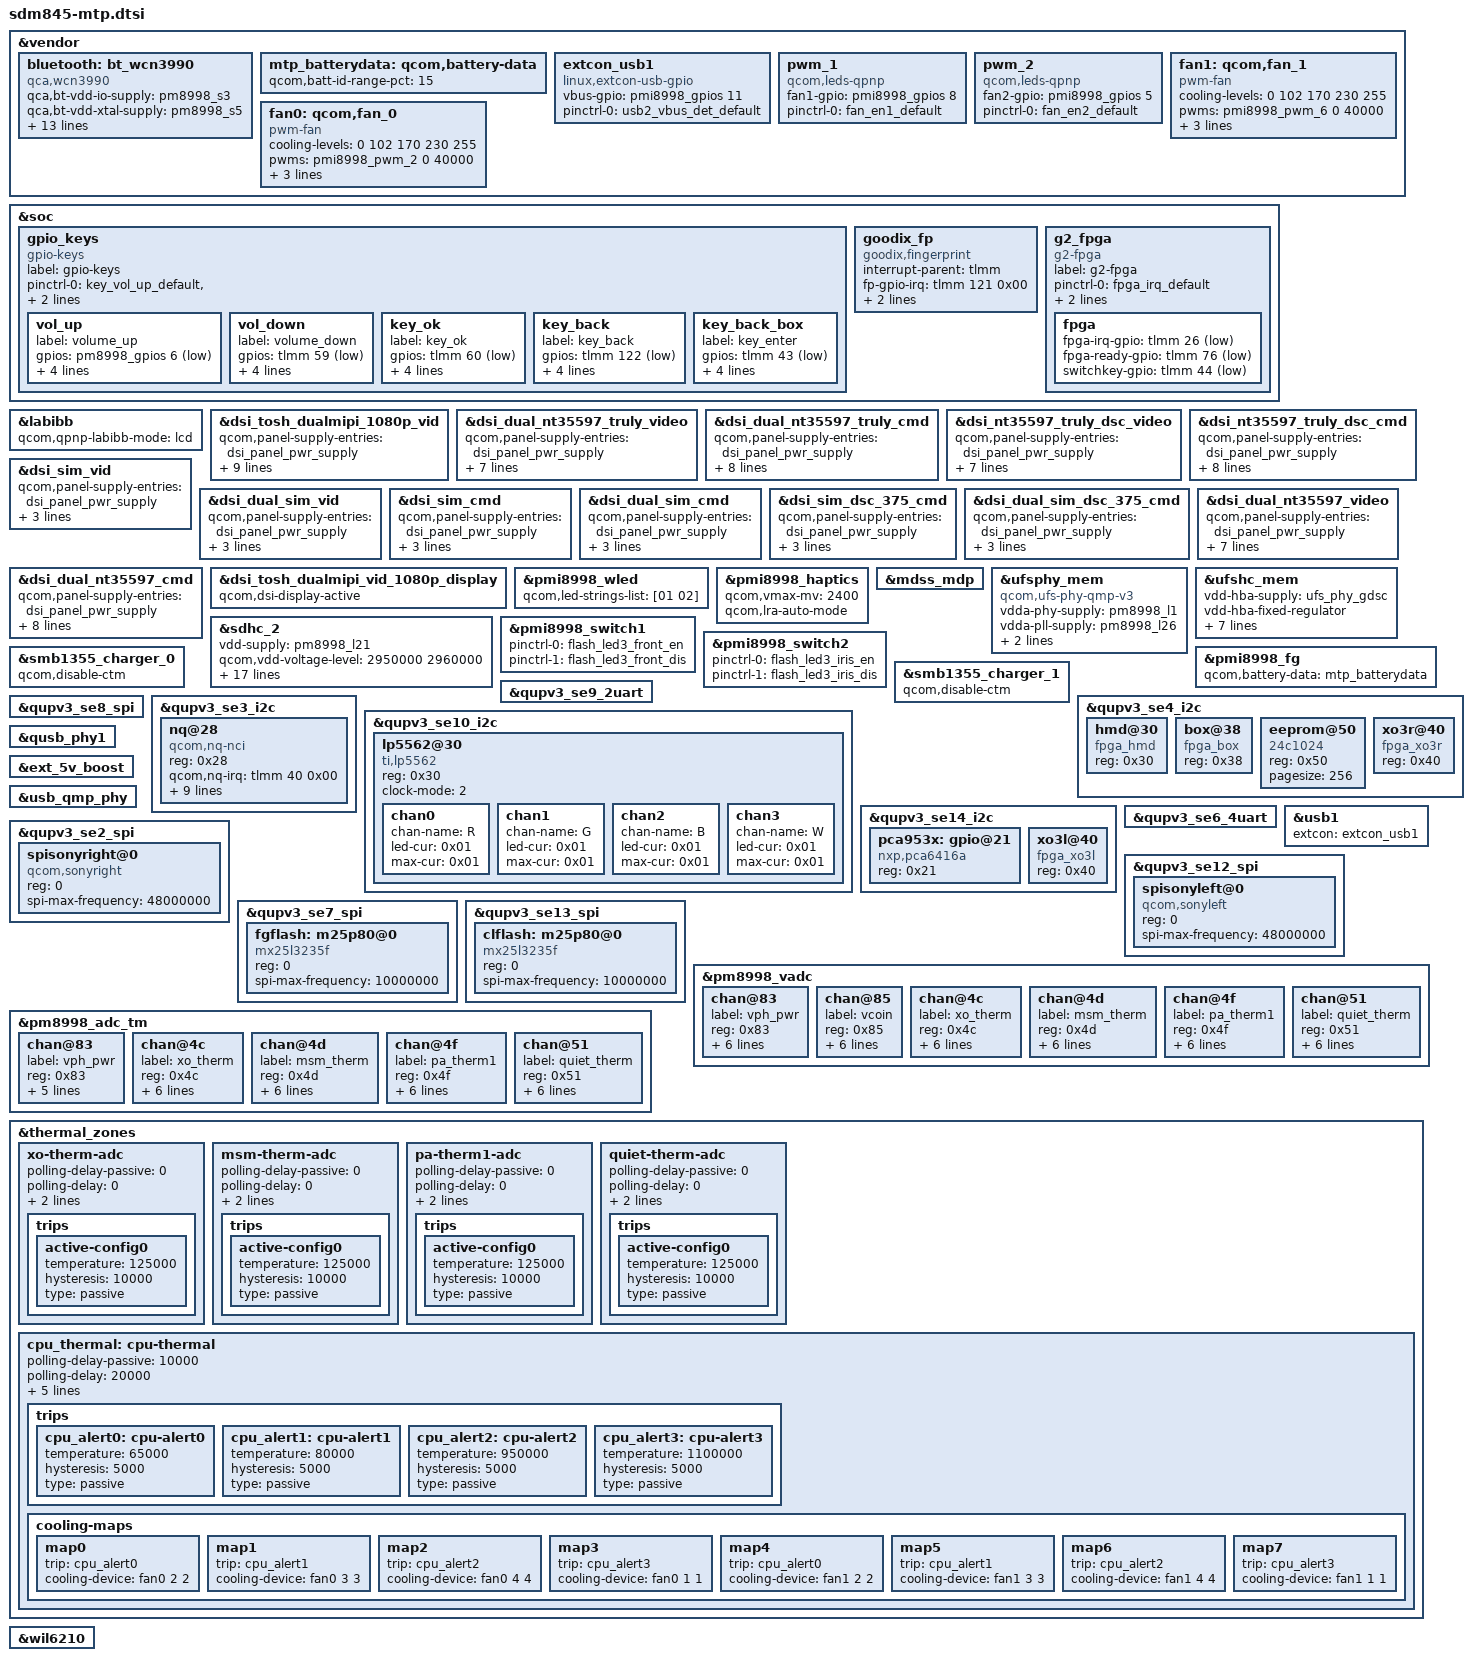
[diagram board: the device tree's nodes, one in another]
/* Copyright (c) 2016-2018, The Linux Foundation. All rights reserved.
 *
 * This program is free software; you can redistribute it and/or modify
 * it under the terms of the GNU General Public License version 2 and
 * only version 2 as published by the Free Software Foundation.
 *
 * This program is distributed in the hope that it will be useful,
 * but WITHOUT ANY WARRANTY; without even the implied warranty of
 * MERCHANTABILITY or FITNESS FOR A PARTICULAR PURPOSE.  See the
 * GNU General Public License for more details.
 */

#include <dt-bindings/gpio/gpio.h>
#include "sdm845-pmic-overlay.dtsi"
#include "sdm845-pinctrl-overlay.dtsi"
#include "sdm845-camera-sensor-mtp.dtsi"
#include "smb1355.dtsi"

&vendor {
	bluetooth: bt_wcn3990 {
		compatible = "qca,wcn3990";
		qca,bt-vdd-io-supply = <&pm8998_s3>;
		qca,bt-vdd-xtal-supply = <&pm8998_s5>;
		qca,bt-vdd-core-supply = <&pm8998_l7>;
		qca,bt-vdd-pa-supply = <&pm8998_l17>;
		qca,bt-vdd-ldo-supply = <&pm8998_l25>;

		qca,bt-vdd-io-voltage-level = <1352000 1352000>;
		qca,bt-vdd-xtal-voltage-level = <2040000 2040000>;
		qca,bt-vdd-core-voltage-level = <1800000 1800000>;
		qca,bt-vdd-pa-voltage-level = <1304000 1304000>;
		qca,bt-vdd-ldo-voltage-level = <3312000 3312000>;

		qca,bt-vdd-io-current-level = <1>; /* LPM/PFM */
		qca,bt-vdd-xtal-current-level = <1>; /* LPM/PFM */
		qca,bt-vdd-core-current-level = <1>; /* LPM/PFM */
		qca,bt-vdd-pa-current-level = <1>; /* LPM/PFM */
		qca,bt-vdd-ldo-current-level = <1>; /* LPM/PFM */
	};
};

&soc {
		gpio_keys {
                compatible = "gpio-keys";
                label = "gpio-keys";
                pinctrl-names = "default";
                
		/*pinctrl-0 = <&key_vol_up_default
			     &key_cam_snapshot_default
			     &key_cam_focus_default>;*/
                pinctrl-0 = <&key_vol_up_default
                             &key_vol_down_default
                            // &key_menu_default
                             &key_ok_default
                             //&key_up_default
                             //&key_down_default
                             //&key_left_default
                             &key_back_default
                             //&key_right_default
                             &key_back_box_default
			     //&key_switch_default
			     //&key_switch_backup_default
			    >;
	        vol_up {
                        label = "volume_up";
                        gpios = <&pm8998_gpios 6 GPIO_ACTIVE_LOW>;
                        linux,input-type = <1>;
                        linux,code = <115>;
                        //gpio-key,wakeup;
                        debounce-interval = <15>;
                        linux,can-disable;
                };
                vol_down {
                        label = "volume_down";
                        gpios = <&tlmm 59 GPIO_ACTIVE_LOW>;
                        linux,input-type = <1>;
                        linux,code = <114>;
                        //gpio-key,wakeup;
                        debounce-interval = <15>;
                        linux,can-disable;
                };
	
                 key_ok{
                        label = "key_ok";
                        gpios = <&tlmm 60 GPIO_ACTIVE_LOW>;
                        linux,input-type = <1>;
                        linux,code = <353>;
                        //gpio-key,wakeup;
                        debounce-interval = <15>;
                        linux,can-disable;
                }; 
		/*key_switch{
                        label = "key_switch";
                        gpios = <&tlmm 44 GPIO_ACTIVE_LOW>;
                        linux,input-type = <1>;
                        linux,code = <600>;
                        //gpio-key,wakeup;
                        debounce-interval = <15>;
                        linux,can-disable;
                }; 

                key_switch_backup{
                        label = "key_switch_backup";
                        gpios = <&tlmm 125 GPIO_ACTIVE_LOW>;
                        linux,input-type = <1>;
                        linux,code = <601>;
                        //gpio-key,wakeup;
                        debounce-interval = <15>;
                        linux,can-disable;
                }; 

                key_up{
                        label = "key_up";
                        gpios = <&tlmm 44 GPIO_ACTIVE_LOW>;//61
                        linux,input-type = <1>;
                        linux,code = <103>;
                        //gpio-key,wakeup;
                        debounce-interval = <15>;
                        linux,can-disable;
                };

                 key_down{
                        label = "key_down";
                        gpios = <&tlmm 125 GPIO_ACTIVE_LOW>;//62
                        linux,input-type = <1>;
                        linux,code = <108>;
                        //gpio-key,wakeup;
                        debounce-interval = <15>;
                        linux,can-disable;
                };
                key_left{
                        label = "key_left";
                        gpios = <&tlmm 62 GPIO_ACTIVE_LOW>;//63
                        linux,input-type = <1>;
                        linux,code = <105>;
                        //gpio-key,wakeup;
                        debounce-interval = <15>;
                        linux,can-disable;

                };*/
                key_back{
                        label = "key_back";
                        gpios = <&tlmm 122 GPIO_ACTIVE_LOW>;
                        linux,input-type = <1>;
                        linux,code = <158>;
                        //gpio-key,wakeup;
                        debounce-interval = <15>;
                        linux,can-disable;
                };

               /* key_right{
                        label = "key_right";
                        gpios = <&tlmm 87 GPIO_ACTIVE_LOW>;
                        linux,input-type = <1>;
                        linux,code = <106>;
                        //gpio-key,wakeup;
                        debounce-interval = <15>;
                        linux,can-disable;
                };*/
               key_back_box{
                        label = "key_enter";
                        gpios = <&tlmm 43 GPIO_ACTIVE_LOW>;
                        linux,input-type = <1>;
                        linux,code = <158>;
                        //gpio-key,wakeup;
                        debounce-interval = <15>;
                        linux,can-disable;
                };

           /*    key_menu{
                        label = "key_menu";
                        gpios = <&tlmm 44 GPIO_ACTIVE_LOW>;
                        linux,input-type = <1>;
                        linux,code = <102>;
                        //gpio-key,wakeup;
                        debounce-interval = <15>;
                        linux,can-disable;
                };
*/
               
           

	};
        
    //goodix GF3206 fp
        goodix_fp{
		compatible = "goodix,fingerprint";

		interrupt-parent = <&tlmm>;

		fp-gpio-irq = <&tlmm 121 0x00>;

		fp-gpio-reset = <&tlmm 91 0x00>;
                
                vdd-fp-supply = <&pm8998_l19>;

		status = "ok";
        };

        g2_fpga{
            compatible = "g2-fpga";
            label = "g2-fpga";
            pinctrl-names = "default";
            pinctrl-0 = <&fpga_irq_default>;
            pinctrl-1 = <&fpga_ready_default>;
	    pinctrl-2 = <&switchkey_default>;
            fpga{
                fpga-irq-gpio = <&tlmm 26 GPIO_ACTIVE_LOW>;
                fpga-ready-gpio = <&tlmm 76 GPIO_ACTIVE_LOW>;
		switchkey-gpio = <&tlmm 44 GPIO_ACTIVE_LOW>;
            };
        };
};


&labibb {
	status = "ok";
	qcom,qpnp-labibb-mode = "lcd";
};

//chad add nedplus begin
//&dsi_tosh_dualmipi_vid {
&dsi_tosh_dualmipi_1080p_vid {
	qcom,panel-supply-entries = <&dsi_panel_pwr_supply>;
	qcom,mdss-dsi-bl-pmic-control-type = "bl_ctrl_wled";//it should be not used
	qcom,mdss-dsi-bl-min-level = <1>;
	qcom,mdss-dsi-bl-max-level = <4095>;
	qcom,mdss-dsi-mode-sel-gpio-state = "dual_port";
        qcom,platform-pwr-en = <&tlmm 114 0>;//control 10v for sony panel
	qcom,platform-tc-gpio = <&tlmm 24 0>;//pull up 1.2v for toshiba
	qcom,platform-reset-gpio = <&tlmm 6 0>;
        qcom,platform-stby-gpio = <&tlmm 10 0>;

};
//chad add nedplus end


&dsi_dual_nt35597_truly_video {
	qcom,panel-supply-entries = <&dsi_panel_pwr_supply>;
	qcom,mdss-dsi-bl-pmic-control-type = "bl_ctrl_wled";
	qcom,mdss-dsi-bl-min-level = <1>;
	qcom,mdss-dsi-bl-max-level = <4095>;
	qcom,mdss-dsi-mode-sel-gpio-state = "dual_port";
	qcom,panel-mode-gpio = <&tlmm 52 0>;
	qcom,platform-reset-gpio = <&tlmm 6 0>;
};

&dsi_dual_nt35597_truly_cmd {
	qcom,panel-supply-entries = <&dsi_panel_pwr_supply>;
	qcom,mdss-dsi-bl-pmic-control-type = "bl_ctrl_wled";
	qcom,mdss-dsi-bl-min-level = <1>;
	qcom,mdss-dsi-bl-max-level = <4095>;
	qcom,mdss-dsi-mode-sel-gpio-state = "dual_port";
	qcom,panel-mode-gpio = <&tlmm 52 0>;
	qcom,platform-reset-gpio = <&tlmm 6 0>;
	qcom,platform-te-gpio = <&tlmm 10 0>;
};

&dsi_nt35597_truly_dsc_video {
	qcom,panel-supply-entries = <&dsi_panel_pwr_supply>;
	qcom,mdss-dsi-bl-pmic-control-type = "bl_ctrl_wled";
	qcom,mdss-dsi-bl-min-level = <1>;
	qcom,mdss-dsi-bl-max-level = <4095>;
	qcom,mdss-dsi-mode-sel-gpio-state = "single_port";
	qcom,panel-mode-gpio = <&tlmm 52 0>;
	qcom,platform-reset-gpio = <&tlmm 6 0>;
};

&dsi_nt35597_truly_dsc_cmd {
	qcom,panel-supply-entries = <&dsi_panel_pwr_supply>;
	qcom,mdss-dsi-bl-pmic-control-type = "bl_ctrl_wled";
	qcom,mdss-dsi-bl-min-level = <1>;
	qcom,mdss-dsi-bl-max-level = <4095>;
	qcom,mdss-dsi-mode-sel-gpio-state = "single_port";
	qcom,panel-mode-gpio = <&tlmm 52 0>;
	qcom,platform-reset-gpio = <&tlmm 6 0>;
	qcom,platform-te-gpio = <&tlmm 10 0>;
};

&dsi_sim_vid {
	qcom,panel-supply-entries = <&dsi_panel_pwr_supply>;
	qcom,mdss-dsi-bl-pmic-control-type = "bl_ctrl_wled";
	qcom,platform-reset-gpio = <&tlmm 6 0>;
};

&dsi_dual_sim_vid {
	qcom,panel-supply-entries = <&dsi_panel_pwr_supply>;
	qcom,mdss-dsi-bl-pmic-control-type = "bl_ctrl_wled";
	qcom,platform-reset-gpio = <&tlmm 6 0>;
};

&dsi_sim_cmd {
	qcom,panel-supply-entries = <&dsi_panel_pwr_supply>;
	qcom,mdss-dsi-bl-pmic-control-type = "bl_ctrl_wled";
	qcom,platform-reset-gpio = <&tlmm 6 0>;
};

&dsi_dual_sim_cmd {
	qcom,panel-supply-entries = <&dsi_panel_pwr_supply>;
	qcom,mdss-dsi-bl-pmic-control-type = "bl_ctrl_wled";
	qcom,platform-reset-gpio = <&tlmm 6 0>;
};

&dsi_sim_dsc_375_cmd {
	qcom,panel-supply-entries = <&dsi_panel_pwr_supply>;
	qcom,mdss-dsi-bl-pmic-control-type = "bl_ctrl_wled";
	qcom,platform-reset-gpio = <&tlmm 6 0>;
};

&dsi_dual_sim_dsc_375_cmd {
	qcom,panel-supply-entries = <&dsi_panel_pwr_supply>;
	qcom,mdss-dsi-bl-pmic-control-type = "bl_ctrl_wled";
	qcom,platform-reset-gpio = <&tlmm 6 0>;
};

&dsi_dual_nt35597_video {
	qcom,panel-supply-entries = <&dsi_panel_pwr_supply>;
	qcom,mdss-dsi-bl-pmic-control-type = "bl_ctrl_wled";
	qcom,mdss-dsi-bl-min-level = <1>;
	qcom,mdss-dsi-bl-max-level = <4095>;
	qcom,mdss-dsi-mode-sel-gpio-state = "dual_port";
	qcom,panel-mode-gpio = <&tlmm 52 0>;
	qcom,platform-reset-gpio = <&tlmm 6 0>;
};

&dsi_dual_nt35597_cmd {
	qcom,panel-supply-entries = <&dsi_panel_pwr_supply>;
	qcom,mdss-dsi-bl-pmic-control-type = "bl_ctrl_wled";
	qcom,mdss-dsi-bl-min-level = <1>;
	qcom,mdss-dsi-bl-max-level = <4095>;
	qcom,mdss-dsi-mode-sel-gpio-state = "dual_port";
	qcom,panel-mode-gpio = <&tlmm 52 0>;
	qcom,platform-reset-gpio = <&tlmm 6 0>;
	qcom,platform-te-gpio = <&tlmm 10 0>;
};


//chad add for nedplus begin
//&dsi_tosh_dualmipi_vid_display {
&dsi_tosh_dualmipi_vid_1080p_display {
	qcom,dsi-display-active;
};

//chad add for nedplus end 

&pmi8998_wled {
	status = "okay";
	qcom,led-strings-list = [01 02];
};

&pmi8998_haptics {
	qcom,vmax-mv = <2400>;
	qcom,lra-auto-mode;
	status = "okay";
};

&mdss_mdp {
	#cooling-cells = <2>;
};

&ufsphy_mem {
	compatible = "qcom,ufs-phy-qmp-v3";

	vdda-phy-supply = <&pm8998_l1>; /* 0.88v */
	vdda-pll-supply = <&pm8998_l26>; /* 1.2v */
	vdda-phy-max-microamp = <62900>;
	vdda-pll-max-microamp = <18300>;

	status = "ok";
};

&ufshc_mem {
	vdd-hba-supply = <&ufs_phy_gdsc>;
	vdd-hba-fixed-regulator;
	vcc-supply = <&pm8998_l20>;
	vcc-voltage-level = <2950000 2960000>;
	vccq2-supply = <&pm8998_s4>;
	vcc-max-microamp = <600000>;
	vccq2-max-microamp = <600000>;

	qcom,vddp-ref-clk-supply = <&pm8998_l2>;
	qcom,vddp-ref-clk-max-microamp = <100>;

	status = "ok";
};

&sdhc_2 {
	vdd-supply = <&pm8998_l21>;
	qcom,vdd-voltage-level = <2950000 2960000>;
	qcom,vdd-current-level = <200 800000>;

	vdd-io-supply = <&pm8998_l13>;
	qcom,vdd-io-voltage-level = <1808000 2960000>;
	qcom,vdd-io-current-level = <200 22000>;

	pinctrl-names = "active", "sleep", "ds_400KHz",
			"ds_50MHz", "ds_100MHz", "ds_200MHz";
	pinctrl-0 = <&sdc2_clk_on  &sdc2_cmd_on &sdc2_data_on &storage_cd>;
	pinctrl-1 = <&sdc2_clk_off &sdc2_cmd_off &sdc2_data_off &storage_cd>;
	pinctrl-2 = <&sdc2_clk_ds_400KHz
			&sdc2_cmd_ds_400KHz &sdc2_data_ds_400KHz>;
	pinctrl-3 = <&sdc2_clk_ds_50MHz
			&sdc2_cmd_ds_50MHz &sdc2_data_ds_50MHz>;
	pinctrl-4 = <&sdc2_clk_ds_100MHz
			&sdc2_cmd_ds_100MHz &sdc2_data_ds_100MHz>;
	pinctrl-5 = <&sdc2_clk_ds_200MHz
			&sdc2_cmd_ds_200MHz &sdc2_data_ds_200MHz>;

	cd-gpios = <&tlmm 126 GPIO_ACTIVE_HIGH>;

	status = "ok";
};

&pmi8998_switch1 {
	pinctrl-names = "led_enable", "led_disable";
	pinctrl-0 = <&flash_led3_front_en>;
	pinctrl-1 = <&flash_led3_front_dis>;
};

&pmi8998_switch2 {
	pinctrl-names = "led_enable", "led_disable";
	pinctrl-0 = <&flash_led3_iris_en>;
	pinctrl-1 = <&flash_led3_iris_dis>;
};

&vendor {
	mtp_batterydata: qcom,battery-data {
		qcom,batt-id-range-pct = <15>;
		#include "Lenovo_4044A4_6400mAh_PMI8998GUI20058.dtsi"
	};

	extcon_usb1: extcon_usb1 {
		compatible = "linux,extcon-usb-gpio";
		vbus-gpio = <&pmi8998_gpios 11 GPIO_ACTIVE_HIGH>;

		pinctrl-names = "default";
		pinctrl-0 = <&usb2_vbus_det_default>;
	};

	pwm_1: pwm_1 {
		compatible = "qcom,leds-qpnp";
		fan1-gpio = <&pmi8998_gpios 8 0>;

		pinctrl-names = "default";
		pinctrl-0 = <&fan_en1_default>;
	};

	pwm_2: pwm_2 {
		compatible = "qcom,leds-qpnp";
		fan2-gpio = <&pmi8998_gpios 5 0>;

		pinctrl-names = "default";
		pinctrl-0 = <&fan_en2_default>;
	};

	fan1: qcom,fan_1 {
		compatible = "pwm-fan";
		#cooling-cells = <2>;
		cooling-levels = <0 102 170 230 255>;
		pwms = <&pmi8998_pwm_6 0 40000>;
		pwm-names = "fan1";
		#pwm-cells = <2>;
		fan-en-gpio = <&tlmm 92 0>;
		fan0-en-gpio = <&tlmm 123 0>;
	};

	fan0: qcom,fan_0 {
		compatible = "pwm-fan";
		#cooling-cells = <2>;
		cooling-levels = <0 102 170 230 255>;
		pwms = <&pmi8998_pwm_2 0 40000>;
		pwm-names = "fan0";
		#pwm-cells = <2>;
		fan-en-gpio = <&tlmm 92 0>;
		fan1-en-gpio = <&tlmm 124 0>;
	};
};

&pmi8998_fg {
	qcom,battery-data = <&mtp_batterydata>;
};

&smb1355_charger_0 {
	status = "ok";
	qcom,disable-ctm;
};

&smb1355_charger_1 {
	status = "ok";
	qcom,disable-ctm;
};

&qupv3_se9_2uart {
	status = "ok";
};

&qupv3_se8_spi {
	status = "ok";
};

&qupv3_se3_i2c {
	status = "ok";
    	nq@28{
		compatible = "qcom,nq-nci";
		reg = <0x28>;
		qcom,nq-irq = <&tlmm 40 0x00>;
		qcom,nq-ven = <&tlmm 12 0x00>;
		qcom,nq-firm = <&tlmm 39 0x00>;
		qcom,nq-clkreq = <&pm8998_gpios 21 0x00>;
		qcom,nq-esepwr = <&tlmm 116 0x00>;
		interrupt-parent = <&tlmm>;
		//qcom,clk-src = "BBCLK3";  //CS3
		interrupts = <40 0>;
		interrupt-names = "nfc_irq";
		pinctrl-names = "nfc_active", "nfc_suspend";
		pinctrl-0 = <&nfc_int_active
			     &nfc_enable_active
			     &nfc_clk_default>;
		pinctrl-1 = <&nfc_int_suspend &nfc_enable_suspend>;
		//clocks = <&clock_rpmh RPMH_LN_BB_CLK3>;  //CS3
		//clock-names = "ref_clk";  //CS3
	};
};

&qupv3_se4_i2c { //for FPGA version
	status = "ok";
	hmd@30 {
		compatible = "fpga_hmd";
		reg = <0x30>;
	};

	box@38 {
		compatible = "fpga_box";
		reg = <0x38>;
	};

	eeprom@50 {
		compatible = "24c1024";
		reg = <0x50>;
		pagesize = <256>;
	};

	xo3r@40 {
		compatible = "fpga_xo3r";
		reg = <0x40>;
	};
 };

&qupv3_se10_i2c {
        status = "ok";
        lp5562@30 {
                        compatible = "ti,lp5562";
                        reg = <0x30>;
                        clock-mode = /bits/8 <2>;

                        chan0 {
                                chan-name = "R";
                                led-cur = /bits/ 8 <0x01>;
                                max-cur = /bits/ 8 <0x01>;
                        };

                        chan1 {
                                chan-name = "G";
                                led-cur = /bits/ 8 <0x01>;
                                max-cur = /bits/ 8 <0x01>;
                        };

                        chan2 {
                                chan-name = "B";
                                led-cur = /bits/ 8 <0x01>;
                                max-cur = /bits/ 8 <0x01>;
                        };

                        chan3 {
                                chan-name = "W";
                                led-cur = /bits/ 8 <0x01>;
                                max-cur = /bits/ 8 <0x01>;
                           };
             };

};

&qupv3_se14_i2c {
	status = "ok";
	pca953x: gpio@21 {
		compatible = "nxp,pca6416a";
                reg = <0x21>;
	};

	xo3l@40 {
		compatible = "fpga_xo3l";
		reg = <0x40>;
	};
};

&qupv3_se6_4uart {
	status = "ok";
};

&usb1 {
	status = "okay";
	extcon = <&extcon_usb1>;
};

&qusb_phy1 {
	status = "okay";
};

&ext_5v_boost {
	status = "ok";
};

&usb_qmp_phy {
	status = "okay";
};


//chad add for nedplus begin
 &qupv3_se2_spi { 
		status = "ok";
		spisonyright@0{
		compatible ="qcom,sonyright";
		reg = <0>;
		spi-max-frequency = <48000000>;
		}; 
		};

&qupv3_se12_spi { 
		status = "ok";
		spisonyleft@0{
		compatible ="qcom,sonyleft";
		reg = <0>;
		spi-max-frequency = <48000000>;
		}; 
		};

//chad add for nedplus end
//ZD add for spi Flash begin

&qupv3_se7_spi { 
		status = "ok";
		fgflash: m25p80@0 {
		#address-cells = <1>;
		#size-cells = <1>;
		compatible = "mx25l3235f";
		reg = <0>;
		spi-max-frequency = <10000000>;
		//m25p,fast-read;
	};
};

&qupv3_se13_spi { 
		status = "ok";
		clflash: m25p80@0 {
		#address-cells = <1>;
		#size-cells = <1>;
		compatible = "mx25l3235f";
		reg = <0>;
		spi-max-frequency = <10000000>;
		//m25p,fast-read;
	};
};
//ZD add for spi Flash end
&pm8998_vadc {
	chan@83 {
		label = "vph_pwr";
		reg = <0x83>;
		qcom,decimation = <2>;
		qcom,pre-div-channel-scaling = <1>;
		qcom,calibration-type = "absolute";
		qcom,scale-function = <0>;
		qcom,hw-settle-time = <0>;
		qcom,fast-avg-setup = <0>;
	}; 

	chan@85 {
		label = "vcoin";
		reg = <0x85>;
		qcom,decimation = <2>;
		qcom,pre-div-channel-scaling = <1>;
		qcom,calibration-type = "absolute";
		qcom,scale-function = <0>;
		qcom,hw-settle-time = <0>;
		qcom,fast-avg-setup = <0>;
	};

	chan@4c {
		label = "xo_therm";
		reg = <0x4c>;
		qcom,decimation = <2>;
		qcom,pre-div-channel-scaling = <0>;
		qcom,calibration-type = "ratiometric";
		qcom,scale-function = <4>;
		qcom,hw-settle-time = <2>;
		qcom,fast-avg-setup = <0>;
	};

	chan@4d {
		label = "msm_therm";
		reg = <0x4d>;
		qcom,decimation = <2>;
		qcom,pre-div-channel-scaling = <0>;
		qcom,calibration-type = "ratiometric";
		qcom,scale-function = <2>;
		qcom,hw-settle-time = <2>;
		qcom,fast-avg-setup = <0>;
	};

	chan@4f {
		label = "pa_therm1";
		reg = <0x4f>;
		qcom,decimation = <2>;
		qcom,pre-div-channel-scaling = <0>;
		qcom,calibration-type = "ratiometric";
		qcom,scale-function = <2>;
		qcom,hw-settle-time = <2>;
		qcom,fast-avg-setup = <0>;
	};

	chan@51 {
		label = "quiet_therm";
		reg = <0x51>;
		qcom,decimation = <2>;
		qcom,pre-div-channel-scaling = <0>;
		qcom,calibration-type = "ratiometric";
		qcom,scale-function = <2>;
		qcom,hw-settle-time = <2>;
		qcom,fast-avg-setup = <0>;
	};
};

&pm8998_adc_tm {
	chan@83 {
		label = "vph_pwr";
		reg = <0x83>;
		qcom,pre-div-channel-scaling = <1>;
		qcom,calibration-type = "absolute";
		qcom,scale-function = <0>;
		qcom,hw-settle-time = <0>;
		qcom,btm-channel-number = <0x60>;
	};

	chan@4c {
		label = "xo_therm";
		reg = <0x4c>;
		qcom,pre-div-channel-scaling = <0>;
		qcom,calibration-type = "ratiometric";
		qcom,scale-function = <4>;
		qcom,hw-settle-time = <2>;
		qcom,btm-channel-number = <0x68>;
		qcom,thermal-node;
	};

	chan@4d {
		label = "msm_therm";
		reg = <0x4d>;
		qcom,pre-div-channel-scaling = <0>;
		qcom,calibration-type = "ratiometric";
		qcom,scale-function = <2>;
		qcom,hw-settle-time = <2>;
		qcom,btm-channel-number = <0x70>;
		qcom,thermal-node;
	};

	chan@4f {
		label = "pa_therm1";
		reg = <0x4f>;
		qcom,pre-div-channel-scaling = <0>;
		qcom,calibration-type = "ratiometric";
		qcom,scale-function = <2>;
		qcom,hw-settle-time = <2>;
		qcom,btm-channel-number = <0x78>;
		qcom,thermal-node;
	};

	chan@51 {
		label = "quiet_therm";
		reg = <0x51>;
		qcom,pre-div-channel-scaling = <0>;
		qcom,calibration-type = "ratiometric";
		qcom,scale-function = <2>;
		qcom,hw-settle-time = <2>;
		qcom,btm-channel-number = <0x80>;
		qcom,thermal-node;
	};
};

&thermal_zones {
	xo-therm-adc {
		polling-delay-passive = <0>;
		polling-delay = <0>;
		thermal-sensors = <&pm8998_adc_tm 0x4c>;
		thermal-governor = "user_space";

		trips {
			active-config0 {
				temperature = <125000>;
				hysteresis = <10000>;
				type = "passive";
			};
		};
	};

	msm-therm-adc {
		polling-delay-passive = <0>;
		polling-delay = <0>;
		thermal-sensors = <&pm8998_adc_tm 0x4d>;
		thermal-governor = "user_space";

		trips {
			active-config0 {
				temperature = <125000>;
				hysteresis = <10000>;
				type = "passive";
			};
		};
	};

	pa-therm1-adc {
		polling-delay-passive = <0>;
		polling-delay = <0>;
		thermal-sensors = <&pm8998_adc_tm 0x4f>;
		thermal-governor = "user_space";

		trips {
			active-config0 {
				temperature = <125000>;
				hysteresis = <10000>;
				type = "passive";
			};
		};
	};

	quiet-therm-adc {
		polling-delay-passive = <0>;
		polling-delay = <0>;
		thermal-sensors = <&pm8998_adc_tm 0x51>;
		thermal-governor = "user_space";

		trips {
			active-config0 {
				temperature = <125000>;
				hysteresis = <10000>;
				type = "passive";
			};
		};
	};

	 cpu_thermal: cpu-thermal{
			polling-delay-passive = <10000>;
			polling-delay = <20000>;
			thermal-sensors = <&tsens0 1>,
					<&tsens0 2>,
					<&tsens0 3>,
					<&tsens0 4>,
					<&tsens0 7>,
					<&tsens0 8>,
					<&tsens0 9>,
					<&tsens0 10>,
					<&tsens0 11>,
					<&tsens0 12>,
					<&tsens1 1>,
					<&tsens1 2>,
					<&tsens1 7>;
			thermal-governor = "step_wise";
			trips {
				cpu_alert0: cpu-alert0 {
					temperature = <65000>;
					hysteresis = <5000>;
					type = "passive";
				};
				cpu_alert1: cpu-alert1 {
					temperature = <80000>;
					hysteresis = <5000>;
					type = "passive";
				};
				cpu_alert2: cpu-alert2 {
					temperature = <950000>;
					hysteresis = <5000>;
					type = "passive";
				};
				cpu_alert3: cpu-alert3 {
					temperature = <1100000>;
					hysteresis = <5000>;
					type = "passive";
				};
			};

			cooling-maps {
			        map0 {
					trip = <&cpu_alert0>;
					cooling-device =
						<&fan0 2 2>;
				};
				map1 {
					trip = <&cpu_alert1>;
					cooling-device =
						<&fan0 3 3>;
				};
				map2 {
					trip = <&cpu_alert2>;
					cooling-device =
						<&fan0 4 4>;
				};
				map3 {
					trip = <&cpu_alert3>;
					cooling-device =
						<&fan0 1 1>;
				};
				map4 {
					trip = <&cpu_alert0>;
					cooling-device =
						<&fan1 2 2>;
				};
				map5 {
					trip = <&cpu_alert1>;
					cooling-device =
						<&fan1 3 3>;
				};
				map6 {
					trip = <&cpu_alert2>;
					cooling-device =
						<&fan1 4 4>;
				};
				map7 {
					trip = <&cpu_alert3>;
					cooling-device =
						<&fan1 1 1>;
				};
			};
		};
};

&wil6210 {
	status = "ok";
};
